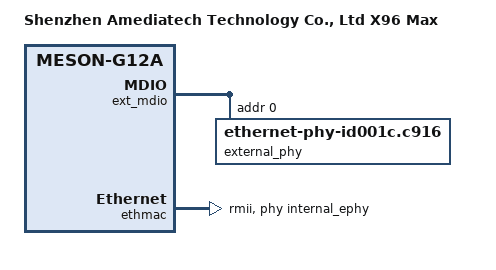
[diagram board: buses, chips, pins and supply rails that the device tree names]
// SPDX-License-Identifier: (GPL-2.0+ OR MIT)
/*
 * Copyright (c) 2018 BayLibre SAS. All rights reserved.
 */

/dts-v1/;

#include "meson-g12a-x96-max.dts"

/ {
	compatible = "amediatech,x96-max-rmii", "amlogic,u200", "amlogic,g12a";
	model = "Shenzhen Amediatech Technology Co., Ltd X96 Max";

};

&ext_mdio {
	external_phy: ethernet-phy@0 {
	      compatible = "ethernet-phy-id001c.c916", "ethernet-phy-ieee802.3-c22";
	      reg = <0>;
	      max-speed = <1000>;
	      eee-broken-1000t;
	};
};

&ethmac {
        pinctrl-0 = <&eth_pins>;
        pinctrl-names = "default";
        status = "okay";
        phy-mode = "rmii";
        phy-handle = <&internal_ephy>;
};
